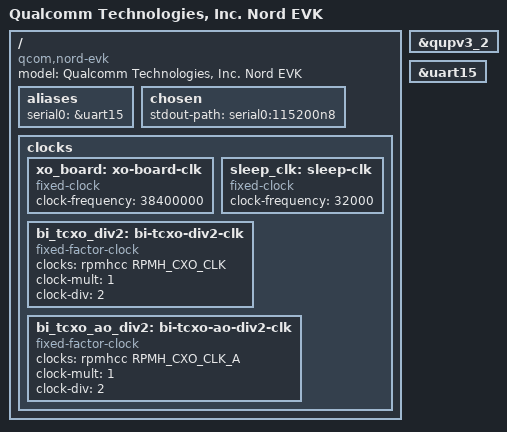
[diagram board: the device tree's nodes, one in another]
// SPDX-License-Identifier: BSD-3-Clause
/*
 * Copyright (c) 2024-2025, Qualcomm Innovation Center, Inc. All rights reserved.
 */

/dts-v1/;

#include "nord.dtsi"

/ {
	model = "Qualcomm Technologies, Inc. Nord EVK";
	compatible = "qcom,nord-evk", "qcom,sa8797p";

	aliases {
		serial0 = &uart15;
	};

	chosen {
		stdout-path = "serial0:115200n8";
	};

	clocks {
		xo_board: xo-board-clk {
			compatible = "fixed-clock";
			clock-frequency = <38400000>;
			#clock-cells = <0>;
		};

		sleep_clk: sleep-clk {
			compatible = "fixed-clock";
			clock-frequency = <32000>;
			#clock-cells = <0>;
		};

		bi_tcxo_div2: bi-tcxo-div2-clk {
			compatible = "fixed-factor-clock";
			#clock-cells = <0>;
			clocks = <&rpmhcc RPMH_CXO_CLK>;
			clock-mult = <1>;
			clock-div = <2>;
		};

		bi_tcxo_ao_div2: bi-tcxo-ao-div2-clk {
			compatible = "fixed-factor-clock";
			#clock-cells = <0>;
			clocks = <&rpmhcc RPMH_CXO_CLK_A>;
			clock-mult = <1>;
			clock-div = <2>;
		};
	};
};

&qupv3_2 {
	status = "okay";
};

&uart15 {
	status = "okay";
};
